# ADC_R_ADC_R_RESULTS_502C6000h register map
Vendor: Texas Instruments
Peripheral module from a debugger description file (folder AM263P).
Registers are 16-bit, read-only, reset 0x0 unless marked. A register's access mark holds for its fields unless they carry their own. Offsets are as the file gives them; lines under a group give offsets from that group; [hi:lo] are bit positions; {n}, {i} and the like mark numbered series; 'fields as' and 'values as' point back to an identical list; <NAME> marks a mode.

## ADC_R_RESULTS
{0x0+2i} ADC_R_RESULTS_ADCRESULT{i} (i=0..15) — ADC Result {i} Register.
  [15:0] RESULT — ADC Result {i} 16-bit ADC result. After the ADC completes a conversion of SOC{i}, the digital result is placed in this bit field.
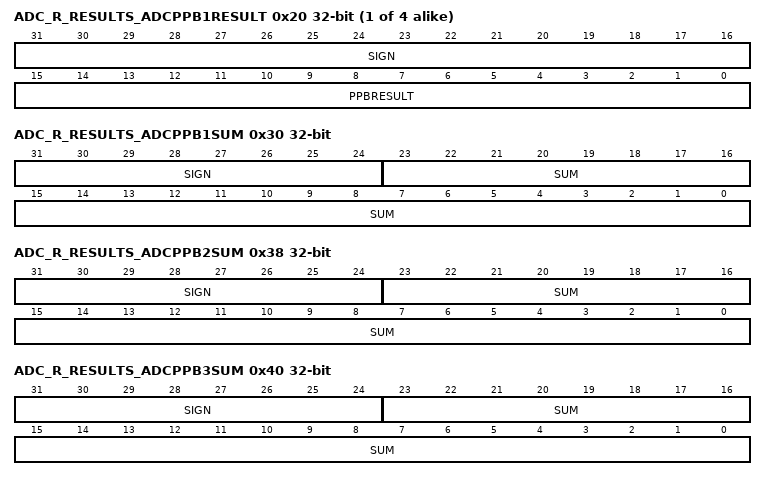
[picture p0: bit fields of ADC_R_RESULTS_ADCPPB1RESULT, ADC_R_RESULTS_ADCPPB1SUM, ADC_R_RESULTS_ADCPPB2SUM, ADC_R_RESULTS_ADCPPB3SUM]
{0x1C+4i} ADC_R_RESULTS_ADCPPB{i}RESULT 32-bit (i=1..4) — ADC Post Processing Block {i} Result Register.
  [31:16] SIGN — Sign Extended Bits. These bits reflect the same value as bit 16. NOTE: If the conversion associated with this Post Processing Block is a 12-bit conversion, the SIGN bits extend down to bit 12, and all reflect the same value as bit 12.
  [15:0] PPBRESULT — ADC Post Processing Block Result {i} The result of the offset/reference subtraction post conversion processing is stored in this register. This result is available 1 SYSCLK cycle after the associated ADCRESULT is available, unless multiple PPBs point to the same SOC. In the case of multiple PPBs associated with the same SOC, the lowest numbered PPB's result will be availble 1 SYSCLK cycle after the associated ADCRESULT and subsequent results [in order from lowest numbered PPB to highest] will each become available every 2-3 SYSCLK cycles [refer to the TRM for more detailed timing information]. If ADCINTFLG is polled to determine when to read the PPBRESULT, it may be necessary to add one or more NOP instructions to ensure that the updated post conversion processing result has posted to the register. NOTE: If the conversion associated with this Post Processing Block is a 12-bit conversion, the PPBRESULT bits are limited to bits 12:0.
0x30 ADC_R_RESULTS_ADCPPB1SUM 32-bit — ADC PPB 1 Final Sum Result Register.
  [31:24] SIGN — Sign Extended Bits. These bits reflect the same value as bit 23.
  [23:0] SUM — Post Processing Block 1 Oversampling Final Sum. When either a count-match event occurs [PCOUNT = LIMIT] or PPB1 receives a sync. event, the value of PSUM is loaded into this register. In the case of a count-match event, the sum loaded into this register includes the value from the most recent conversion. The value from PSUM will be right shifted by the amount specified in the SHIFT register before being loaded into the final SUM result register. This result is available 1 SYSCLK cycle after the associated ADCPPB1RESULT is available [only in case of a count-match event]. This will be 2 SYSCLK cycles after the associated ADCRESULT is available, unless multiple PPBs point to the same SOC [refer to the ADCPPB1RESULT timing information].
0x34 ADC_R_RESULTS_ADCPPB1COUNT — ADC PPB1 Final Conversion Count Register.
  [9:0] COUNT — Post Processing Block 1 Oversampling Final Count. When either a count-match event occurs [PCOUNT = LIMIT] or PPB1 receives a sync. event, the value of PCOUNT is loaded into this register. This result is available 1 SYSCLK cycle after the associated ADCPPB1RESULT is available [only in case of a count-match event]. This will be 2 SYSCLK cycles after the associated ADCRESULT is available, unless multiple PPBs point to the same SOC [refer to the ADCPPB1RESULT timing information].
0x38 ADC_R_RESULTS_ADCPPB2SUM 32-bit — ADC PPB 2 Final Sum Result Register.
  [31:24] SIGN — Sign Extended Bits. These bits reflect the same value as bit 23.
  [23:0] SUM — Post Processing Block 2 Oversampling Final Sum. When either a count-match event occurs [PCOUNT = LIMIT] or PPB2 receives a sync. event, the value of PSUM is loaded into this register. In the case of a count-match event, the sum loaded into this register includes the value from the most recent conversion. The value from PSUM will be right shifted by the amount specified in the SHIFT register before being loaded into the final SUM result register. This result is available 1 SYSCLK cycle after the associated ADCPPB2RESULT is available [only in case of a count-match event]. This will be 2 SYSCLK cycles after the associated ADCRESULT is available, unless multiple PPBs point to the same SOC [refer to the ADCPPB2RESULT timing information].
0x3C ADC_R_RESULTS_ADCPPB2COUNT — ADC PPB2 Final Conversion Count Register.
  [9:0] COUNT — Post Processing Block 2 Oversampling Final Count. When either a count-match event occurs [PCOUNT = LIMIT] or PPB2 receives a sync. event, the value of PCOUNT is loaded into this register. This result is available 1 SYSCLK cycle after the associated ADCPPB2RESULT is available [only in case of a count-match event]. This will be 2 SYSCLK cycles after the associated ADCRESULT is available, unless multiple PPBs point to the same SOC [refer to the ADCPPB2RESULT timing information].
0x40 ADC_R_RESULTS_ADCPPB3SUM 32-bit — ADC PPB 3 Final Sum Result Register.
  [31:24] SIGN — Sign Extended Bits. These bits reflect the same value as bit 23.
  [23:0] SUM — Post Processing Block 3 Oversampling Final Sum. When either a count-match event occurs [PCOUNT = LIMIT] or PPB3 receives a sync. event, the value of PSUM is loaded into this register. In the case of a count-match event, the sum loaded into this register includes the value from the most recent conversion. The value from PSUM will be right shifted by the amount specified in the SHIFT register before being loaded into the final SUM result register. This result is available 1 SYSCLK cycle after the associated ADCPPB3RESULT is available [only in case of a count-match event]. This will be 2 SYSCLK cycles after the associated ADCRESULT is available, unless multiple PPBs point to the same SOC [refer to the ADCPPB3RESULT timing information].
0x44 ADC_R_RESULTS_ADCPPB3COUNT — ADC PPB3 Final Conversion Count Register.
  [9:0] COUNT — Post Processing Block 3 Oversampling Final Count. When either a count-match event occurs [PCOUNT = LIMIT] or PPB3 receives a sync. event, the value of PCOUNT is loaded into this register. This result is available 1 SYSCLK cycle after the associated ADCPPB3RESULT is available [only in case of a count-match event]. This will be 2 SYSCLK cycles after the associated ADCRESULT is available, unless multiple PPBs point to the same SOC [refer to the ADCPPB3RESULT timing information].
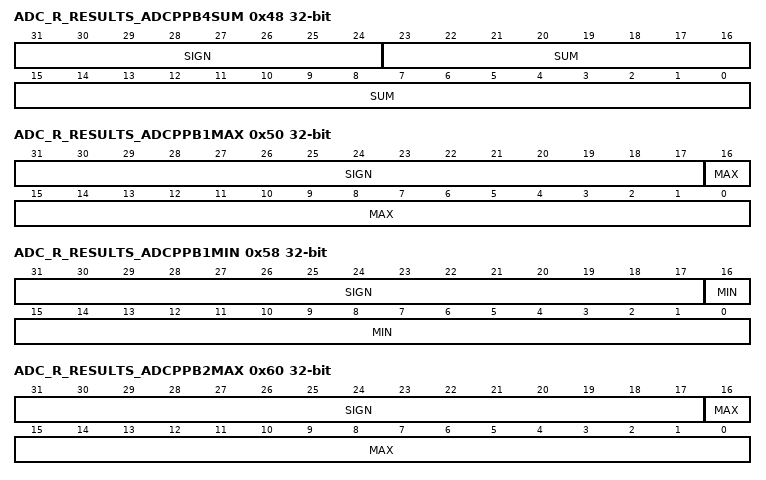
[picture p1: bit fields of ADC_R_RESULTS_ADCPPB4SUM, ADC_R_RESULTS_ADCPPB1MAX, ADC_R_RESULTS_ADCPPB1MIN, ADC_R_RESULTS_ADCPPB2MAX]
0x48 ADC_R_RESULTS_ADCPPB4SUM 32-bit — ADC PPB 4 Final Sum Result Register.
  [31:24] SIGN — Sign Extended Bits. These bits reflect the same value as bit 23.
  [23:0] SUM — Post Processing Block 4 Oversampling Final Sum. When either a count-match event occurs [PCOUNT = LIMIT] or PPB4 receives a sync. event, the value of PSUM is loaded into this register. In the case of a count-match event, the sum loaded into this register includes the value from the most recent conversion. The value from PSUM will be right shifted by the amount specified in the SHIFT register before being loaded into the final SUM result register. This result is available 1 SYSCLK cycle after the associated ADCPPB4RESULT is available [only in case of a count-match event]. This will be 2 SYSCLK cycles after the associated ADCRESULT is available, unless multiple PPBs point to the same SOC [refer to the ADCPPB4RESULT timing information].
0x4C ADC_R_RESULTS_ADCPPB4COUNT — ADC PPB4 Final Conversion Count Register.
  [9:0] COUNT — Post Processing Block 4 Oversampling Final Count. When either a count-match event occurs [PCOUNT = LIMIT] or PPB4 receives a sync. event, the value of PCOUNT is loaded into this register. This result is available 1 SYSCLK cycle after the associated ADCPPB4RESULT is available [only in case of a count-match event]. This will be 2 SYSCLK cycles after the associated ADCRESULT is available, unless multiple PPBs point to the same SOC [refer to the ADCPPB4RESULT timing information].
0x50 ADC_R_RESULTS_ADCPPB1MAX 32-bit — ADC PPB 1 Final Max Result Register.
  [31:17] SIGN — Sign Extended Bits. These bits reflect the same value as bit 16.
  [16:0] MAX — Post Processing Block 1 Oversampling Final Max. When either a count-match event occurs [PCOUNT = LIMIT] or PPB1 receives a sync. event, the value of PMAX is loaded into this register. In the case of a count-match event, the max loaded into this register includes the value from the most recent conversion. This result is available 1 SYSCLK cycle after the associated ADCPPB1RESULT is available [only when a count-match event occurs]. This will be 2 SYSCLK cycles after the associated ADCRESULT is available, unless multiple PPBs point to the same SOC [refer to the ADCPPB1RESULT timing information].
0x54 ADC_R_RESULTS_ADCPPB1MAXI — ADC PPB 1 Final Max Index Result Register.
  [9:0] MAXI — Post Processing Block 1 Oversampling Final Index of the Max. When either a count-match event occurs [PCOUNT = LIMIT] or PPB1 receives a sync. event, the value of PMAXI is loaded into this register. In the case of a count-match event, the max index loaded into this register includes the value from the most recent conversion. This result is available 1 SYSCLK cycle after the associated ADCPPB1RESULT is available [only in case of a count-match event]. This will be 2 SYSCLK cycles after the associated ADCRESULT is available, unless multiple PPBs point to the same SOC [refer to the ADCPPB1RESULT timing information].
0x58 ADC_R_RESULTS_ADCPPB1MIN 32-bit — ADC PPB 1 Final Min Result Register.
  [31:17] SIGN — Sign Extended Bits. These bits reflect the same value as bit 16.
  [16:0] MIN — Post Processing Block 1 Oversampling Final Min. When either a count-match event occurs [PCOUNT = LIMIT] or PPB1 receives a sync. event, the value of PMIN is loaded into this register. In the case of a count-match event, the max loaded into this register includes the value from the most recent conversion. This result is available 1 SYSCLK cycle after the associated ADCPPB1RESULT is available [only in case of a count-match event]. This will be 2 SYSCLK cycles after the associated ADCRESULT is available, unless multiple PPBs point to the same SOC [refer to the ADCPPB1RESULT timing information].
0x5C ADC_R_RESULTS_ADCPPB1MINI — ADC PPB 1 Final Min Index Result Register.
  [9:0] MINI — Post Processing Block 1 Oversampling Final Index of the Min. When either a count-match event occurs [PCOUNT = LIMIT] or PPB1 receives a sync. event, the value of PMINI is loaded into this register. In the case of a count-match event, the min index loaded into this register includes the value from the most recent conversion. This result is available 1 SYSCLK cycle after the associated ADCPPB1RESULT is available [only in case of a count-match event]. This will be 2 SYSCLK cycles after the associated ADCRESULT is available, unless multiple PPBs point to the same SOC [refer to the ADCPPB1RESULT timing information].
0x60 ADC_R_RESULTS_ADCPPB2MAX 32-bit — ADC PPB 2 Final Max Result Register.
  [31:17] SIGN — Sign Extended Bits. These bits reflect the same value as bit 16.
  [16:0] MAX — Post Processing Block 2 Oversampling Final Max. When either a count-match event occurs [PCOUNT = LIMIT] or PPB2 receives a sync. event, the value of PMAX is loaded into this register. In the case of a count-match event, the max loaded into this register includes the value from the most recent conversion. This result is available 1 SYSCLK cycle after the associated ADCPPB2RESULT is available [only when a count-match event occurs]. This will be 2 SYSCLK cycles after the associated ADCRESULT is available, unless multiple PPBs point to the same SOC [refer to the ADCPPB2RESULT timing information].
0x64 ADC_R_RESULTS_ADCPPB2MAXI — ADC PPB 2 Final Max Index Result Register.
  [9:0] MAXI — Post Processing Block 2 Oversampling Final Index of the Max. When either a count-match event occurs [PCOUNT = LIMIT] or PPB2 receives a sync. event, the value of PMAXI is loaded into this register. In the case of a count-match event, the max index loaded into this register includes the value from the most recent conversion. This result is available 1 SYSCLK cycle after the associated ADCPPB2RESULT is available [only in case of a count-match event]. This will be 2 SYSCLK cycles after the associated ADCRESULT is available, unless multiple PPBs point to the same SOC [refer to the ADCPPB2RESULT timing information].
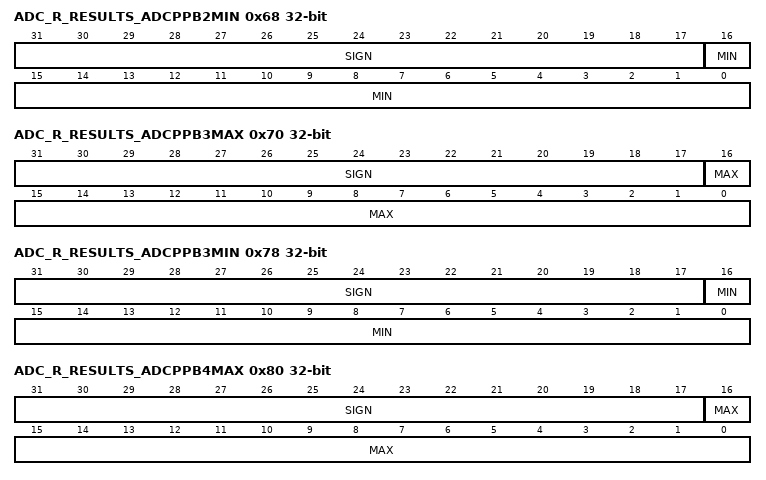
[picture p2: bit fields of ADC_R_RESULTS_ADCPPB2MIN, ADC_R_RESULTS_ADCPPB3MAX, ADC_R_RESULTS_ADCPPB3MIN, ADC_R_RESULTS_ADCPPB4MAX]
0x68 ADC_R_RESULTS_ADCPPB2MIN 32-bit — ADC PPB 2 Final Min Result Register.
  [31:17] SIGN — Sign Extended Bits. These bits reflect the same value as bit 16.
  [16:0] MIN — Post Processing Block 2 Oversampling Final Min. When either a count-match event occurs [PCOUNT = LIMIT] or PPB2 receives a sync. event, the value of PMIN is loaded into this register. In the case of a count-match event, the max loaded into this register includes the value from the most recent conversion. This result is available 1 SYSCLK cycle after the associated ADCPPB2RESULT is available [only in case of a count-match event]. This will be 2 SYSCLK cycles after the associated ADCRESULT is available, unless multiple PPBs point to the same SOC [refer to the ADCPPB2RESULT timing information].
0x6C ADC_R_RESULTS_ADCPPB2MINI — ADC PPB 2 Final Min Index Result Register.
  [9:0] MINI — Post Processing Block 2 Oversampling Final Index of the Min. When either a count-match event occurs [PCOUNT = LIMIT] or PPB2 receives a sync. event, the value of PMINI is loaded into this register. In the case of a count-match event, the min index loaded into this register includes the value from the most recent conversion. This result is available 1 SYSCLK cycle after the associated ADCPPB2RESULT is available [only in case of a count-match event]. This will be 2 SYSCLK cycles after the associated ADCRESULT is available, unless multiple PPBs point to the same SOC [refer to the ADCPPB2RESULT timing information].
0x70 ADC_R_RESULTS_ADCPPB3MAX 32-bit — ADC PPB 3 Final Max Result Register.
  [31:17] SIGN — Sign Extended Bits. These bits reflect the same value as bit 16.
  [16:0] MAX — Post Processing Block 3 Oversampling Final Max. When either a count-match event occurs [PCOUNT = LIMIT] or PPB3 receives a sync. event, the value of PMAX is loaded into this register. In the case of a count-match event, the max loaded into this register includes the value from the most recent conversion. This result is available 1 SYSCLK cycle after the associated ADCPPB3RESULT is available [only when a count-match event occurs]. This will be 2 SYSCLK cycles after the associated ADCRESULT is available, unless multiple PPBs point to the same SOC [refer to the ADCPPB3RESULT timing information].
0x74 ADC_R_RESULTS_ADCPPB3MAXI — ADC PPB 3 Final Max Index Result Register.
  [9:0] MAXI — Post Processing Block 3 Oversampling Final Index of the Max. When either a count-match event occurs [PCOUNT = LIMIT] or PPB3 receives a sync. event, the value of PMAXI is loaded into this register. In the case of a count-match event, the max index loaded into this register includes the value from the most recent conversion. This result is available 1 SYSCLK cycle after the associated ADCPPB3RESULT is available [only in case of a count-match event]. This will be 2 SYSCLK cycles after the associated ADCRESULT is available, unless multiple PPBs point to the same SOC [refer to the ADCPPB3RESULT timing information].
0x78 ADC_R_RESULTS_ADCPPB3MIN 32-bit — ADC PPB 3 Final Min Result Register.
  [31:17] SIGN — Sign Extended Bits. These bits reflect the same value as bit 16.
  [16:0] MIN — Post Processing Block 3 Oversampling Final Min. When either a count-match event occurs [PCOUNT = LIMIT] or PPB3 receives a sync. event, the value of PMIN is loaded into this register. In the case of a count-match event, the max loaded into this register includes the value from the most recent conversion. This result is available 1 SYSCLK cycle after the associated ADCPPB3RESULT is available [only in case of a count-match event]. This will be 2 SYSCLK cycles after the associated ADCRESULT is available, unless multiple PPBs point to the same SOC [refer to the ADCPPB3RESULT timing information].
0x7C ADC_R_RESULTS_ADCPPB3MINI — ADC PPB 3 Final Min Index Result Register.
  [9:0] MINI — Post Processing Block 3 Oversampling Final Index of the Min. When either a count-match event occurs [PCOUNT = LIMIT] or PPB3 receives a sync. event, the value of PMINI is loaded into this register. In the case of a count-match event, the min index loaded into this register includes the value from the most recent conversion. This result is available 1 SYSCLK cycle after the associated ADCPPB3RESULT is available [only in case of a count-match event]. This will be 2 SYSCLK cycles after the associated ADCRESULT is available, unless multiple PPBs point to the same SOC [refer to the ADCPPB3RESULT timing information].
0x80 ADC_R_RESULTS_ADCPPB4MAX 32-bit — ADC PPB 4 Final Max Result Register.
  [31:17] SIGN — Sign Extended Bits. These bits reflect the same value as bit 16.
  [16:0] MAX — Post Processing Block 4 Oversampling Final Max. When either a count-match event occurs [PCOUNT = LIMIT] or PPB4 receives a sync. event, the value of PMAX is loaded into this register. In the case of a count-match event, the max loaded into this register includes the value from the most recent conversion. This result is available 1 SYSCLK cycle after the associated ADCPPB4RESULT is available [only when a count-match event occurs]. This will be 2 SYSCLK cycles after the associated ADCRESULT is available, unless multiple PPBs point to the same SOC [refer to the ADCPPB4RESULT timing information].
0x84 ADC_R_RESULTS_ADCPPB4MAXI — ADC PPB 4 Final Max Index Result Register.
  [9:0] MAXI — Post Processing Block 4 Oversampling Final Index of the Max. When either a count-match event occurs [PCOUNT = LIMIT] or PPB4 receives a sync. event, the value of PMAXI is loaded into this register. In the case of a count-match event, the max index loaded into this register includes the value from the most recent conversion. This result is available 1 SYSCLK cycle after the associated ADCPPB4RESULT is available [only in case of a count-match event]. This will be 2 SYSCLK cycles after the associated ADCRESULT is available, unless multiple PPBs point to the same SOC [refer to the ADCPPB4RESULT timing information].
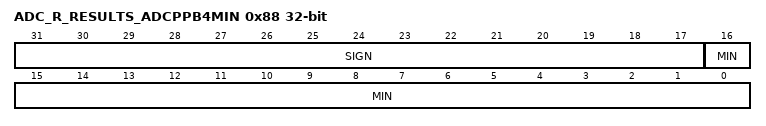
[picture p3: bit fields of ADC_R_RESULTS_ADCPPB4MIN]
0x88 ADC_R_RESULTS_ADCPPB4MIN 32-bit — ADC PPB 4 Final Min Result Register.
  [31:17] SIGN — Sign Extended Bits. These bits reflect the same value as bit 16.
  [16:0] MIN — Post Processing Block 4 Oversampling Final Min. When either a count-match event occurs [PCOUNT = LIMIT] or PPB4 receives a sync. event, the value of PMIN is loaded into this register. In the case of a count-match event, the max loaded into this register includes the value from the most recent conversion. This result is available 1 SYSCLK cycle after the associated ADCPPB4RESULT is available [only in case of a count-match event]. This will be 2 SYSCLK cycles after the associated ADCRESULT is available, unless multiple PPBs point to the same SOC [refer to the ADCPPB4RESULT timing information].
0x8C ADC_R_RESULTS_ADCPPB4MINI — ADC PPB 4 Final Min Index Result Register.
  [9:0] MINI — Post Processing Block 4 Oversampling Final Index of the Min. When either a count-match event occurs [PCOUNT = LIMIT] or PPB4 receives a sync. event, the value of PMINI is loaded into this register. In the case of a count-match event, the min index loaded into this register includes the value from the most recent conversion. This result is available 1 SYSCLK cycle after the associated ADCPPB4RESULT is available [only in case of a count-match event]. This will be 2 SYSCLK cycles after the associated ADCRESULT is available, unless multiple PPBs point to the same SOC [refer to the ADCPPB4RESULT timing information].
